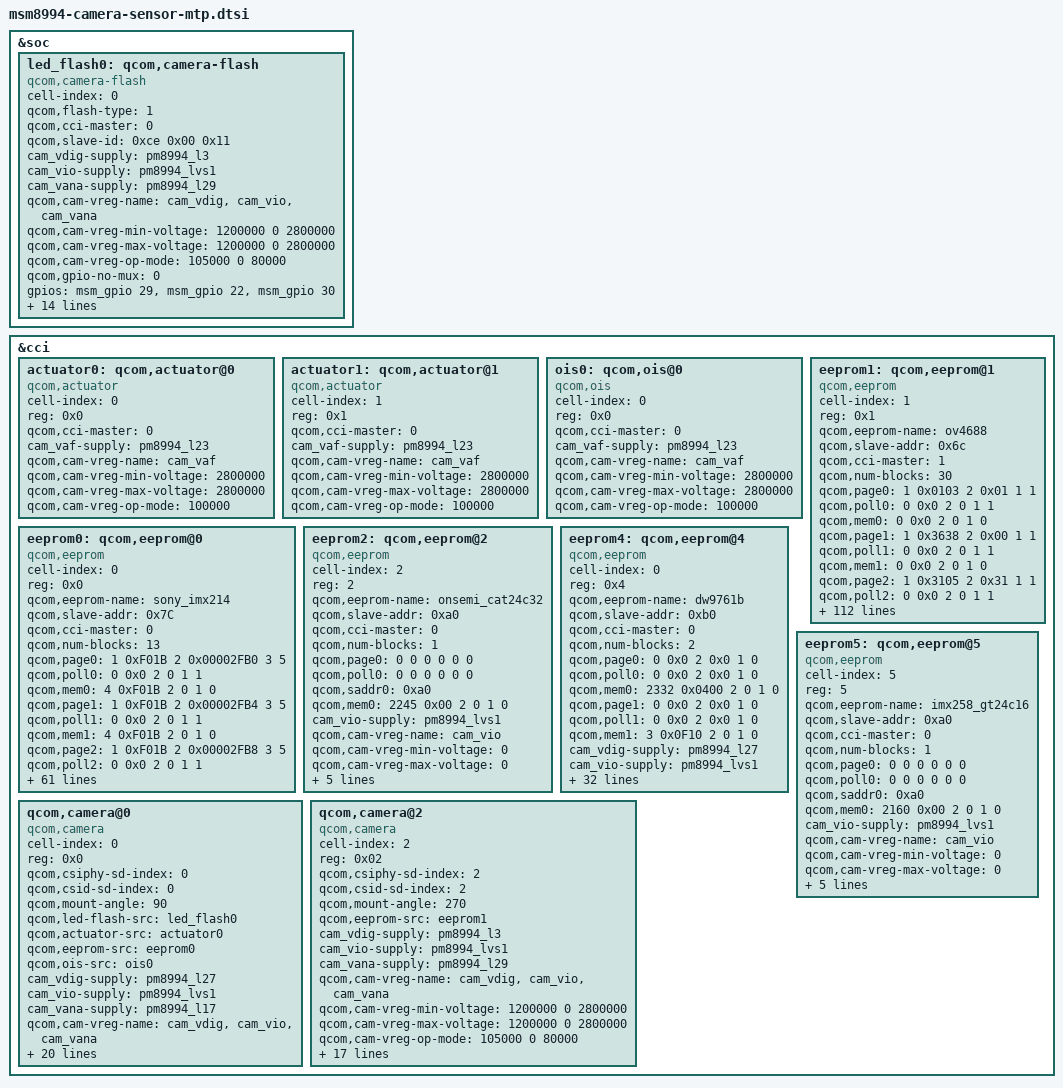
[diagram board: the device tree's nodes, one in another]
/*
 * Copyright (c) 2014-2016, The Linux Foundation. All rights reserved.
 * Copyright (C) 2018 XiaoMi, Inc.
 *
 * This program is free software; you can redistribute it and/or modify
 * it under the terms of the GNU General Public License version 2 and
 * only version 2 as published by the Free Software Foundation.
 *
 * This program is distributed in the hope that it will be useful,
 * but WITHOUT ANY WARRANTY; without even the implied warranty of
 * MERCHANTABILITY or FITNESS FOR A PARTICULAR PURPOSE.  See the
 * GNU General Public License for more details.
 */

&soc {

	led_flash0: qcom,camera-flash {
		cell-index = <0>;
		compatible = "qcom,camera-flash";
		qcom,flash-type = <1>;
		qcom,cci-master = <0>;
        qcom,slave-id = <0xce 0x00 0x11>;

		cam_vdig-supply = <&pm8994_l3>;
		cam_vio-supply = <&pm8994_lvs1>;
		cam_vana-supply = <&pm8994_l29>;
		qcom,cam-vreg-name = "cam_vdig", "cam_vio", "cam_vana";
		qcom,cam-vreg-min-voltage = <1200000 0 2800000>;
		qcom,cam-vreg-max-voltage = <1200000 0 2800000>;
		qcom,cam-vreg-op-mode = <105000 0 80000>;

		qcom,gpio-no-mux = <0>;
		gpios = <&msm_gpio 29 0>,
			<&msm_gpio 22 0>,
			<&msm_gpio 30 0>;
		qcom,gpio-flash-en = <0>;
		qcom,gpio-flash-now = <1>;
		qcom,gpio-flash-reset = <2>;
		qcom,gpio-req-tbl-num = <0 1 2>;
		qcom,gpio-req-tbl-flags = <0 0 0>;
		qcom,gpio-req-tbl-label = "FLASH_EN", "FLASH_NOW", "FLASH_RESET";
		qcom,cam-power-seq-type = "sensor_vreg", "sensor_gpio", "sensor_gpio", "sensor_gpio";
		qcom,cam-power-seq-val = "cam_vio", "sensor_gpio_fl_en", "sensor_gpio_fl_now","sensor_gpio_fl_reset";
		qcom,cam-power-seq-cfg-val = <1 0 0 0>;
		qcom,cam-power-seq-delay = <1 1 1 1>;
	};

};

&cci {
        /*led_flash0: qcom,led-flash@66 {
                cell-index = <0>;
                reg = <0xce>;
                qcom,slave-id = <0xce 0x00 0x11>;
                compatible = "qcom,camera-flash";
                label = "lm3646";
                qcom,flash-type = <1>;
                qcom,gpio-no-mux = <0>;
                gpios = <&msm_gpio 29 0>,
                        <&msm_gpio 22 0>;
                qcom,gpio-flash-en = <0>;
                qcom,gpio-flash-now = <1>;
                qcom,gpio-req-tbl-num = <0 1>;
                qcom,gpio-req-tbl-flags = <0 0>;
                qcom,gpio-req-tbl-label = "FLASH_EN", "FLASH_NOW";
                qcom,cci-master = <0>;
        };*/

	actuator0: qcom,actuator@0 {
		cell-index = <0>;
		reg = <0x0>;
		compatible = "qcom,actuator";
		qcom,cci-master = <0>;
		cam_vaf-supply = <&pm8994_l23>;
		qcom,cam-vreg-name = "cam_vaf";
		qcom,cam-vreg-min-voltage = <2800000>;
		qcom,cam-vreg-max-voltage = <2800000>;
		qcom,cam-vreg-op-mode = <100000>;
	};

	actuator1: qcom,actuator@1 {
		cell-index = <1>;
		reg = <0x1>;
		compatible = "qcom,actuator";
		qcom,cci-master = <0>;
		cam_vaf-supply = <&pm8994_l23>;
		qcom,cam-vreg-name = "cam_vaf";
		qcom,cam-vreg-min-voltage = <2800000>;
		qcom,cam-vreg-max-voltage = <2800000>;
		qcom,cam-vreg-op-mode = <100000>;
	};


	ois0: qcom,ois@0 {
		cell-index = <0>;
		reg = <0x0>;
		compatible = "qcom,ois";
		qcom,cci-master = <0>;
		cam_vaf-supply = <&pm8994_l23>;
		qcom,cam-vreg-name = "cam_vaf";
		qcom,cam-vreg-min-voltage = <2800000>;
		qcom,cam-vreg-max-voltage = <2800000>;
		qcom,cam-vreg-op-mode = <100000>;
	};

	eeprom0: qcom,eeprom@0 {
		cell-index = <0>;
		reg = <0x0>;
		qcom,eeprom-name = "sony_imx214";
		compatible = "qcom,eeprom";
		qcom,slave-addr = <0x7C>;
		qcom,cci-master = <0>;
		qcom,num-blocks = <13>;

		qcom,page0 = <1 0xF01B 2 0x00002FB0 3 5>;
		qcom,poll0 = <0 0x0 2 0 1 1>;
		qcom,mem0 = <4 0xF01B 2 0 1 0>;

		qcom,page1 = <1 0xF01B 2 0x00002FB4 3 5>;
		qcom,poll1 = <0 0x0 2 0 1 1>;
		qcom,mem1 = <4 0xF01B 2 0 1 0>;

		qcom,page2 = <1 0xF01B 2 0x00002FB8 3 5>;
		qcom,poll2 = <0 0x0 2 0 1 1>;
		qcom,mem2 = <4 0xF01B 2 0 1 0>;

		qcom,page3 = <1 0xF01B 2 0x00002FBC 3 5>;
		qcom,poll3 = <0 0x0 2 0 1 1>;
		qcom,mem3 = <4 0xF01B 2 0 1 0>;

		qcom,page4 = <1 0xF01B 2 0x00002FC0 3 5>;
		qcom,poll4 = <0 0x0 2 0 1 1>;
		qcom,mem4 = <4 0xF01B 2 0 1 0>;

		qcom,page5 = <1 0xF01B 2 0x00002FC4 3 5>;
		qcom,poll5 = <0 0x0 2 0 1 1>;
		qcom,mem5 = <4 0xF01B 2 0 1 0>;

		qcom,page6 = <1 0xF01B 2 0x00002FC8 3 5>;
		qcom,poll6 = <0 0x0 2 0 1 1>;
		qcom,mem6 = <4 0xF01B 2 0 1 0>;

		qcom,page7 = <1 0xF01B 2 0x00002FCC 3 5>;
		qcom,poll7 = <0 0x0 2 0 1 1>;
		qcom,mem7 = <4 0xF01B 2 0 1 0>;

		qcom,page8 = <1 0xF01B 2 0x00002FD0 3 5>;
		qcom,poll8 = <0 0x0 2 0 1 1>;
		qcom,mem8 = <4 0xF01B 2 0 1 0>;

		qcom,page9 = <1 0xF01B 2 0x00002FD4 3 5>;
		qcom,poll9 = <0 0x0 2 0 1 1>;
		qcom,mem9 = <4 0xF01B 2 0 1 0>;

		qcom,page10 = <1 0xF01B 2 0x00002FD8 3 5>;
		qcom,poll10 = <0 0x0 2 0 1 1>;
		qcom,mem10 = <4 0xF01B 2 0 1 0>;

		qcom,page11 = <1 0xF01B 2 0x00002FDC 3 5>;
		qcom,poll11 = <0 0x0 2 0 1 1>;
		qcom,mem11 = <4 0xF01B 2 0 1 0>;

		qcom,page12 = <1 0xF01B 2 0x00002FDE 3 5>;
		qcom,poll12 = <0 0x0 2 0 1 1>;
		qcom,mem12 = <4 0xF01B 2 0 1 0>;

		cam_vdig-supply = <&pm8994_l27>;
		cam_vio-supply = <&pm8994_lvs1>;
		cam_vana-supply = <&pm8994_l17>;
		qcom,cam-vreg-name = "cam_vdig", "cam_vio", "cam_vana";
		qcom,cam-vreg-min-voltage = <1050000 0 2700000>;
		qcom,cam-vreg-max-voltage = <1050000 0 2700000>;
		qcom,cam-vreg-op-mode = <105000 0 80000>;
		qcom,gpio-no-mux = <0>;
		pinctrl-names = "cam_default", "cam_suspend";
		pinctrl-0 = <&cam_sensor_mclk0_active &cam_sensor_rear_active>;
		pinctrl-1 = <&cam_sensor_mclk0_suspend &cam_sensor_rear_suspend>;
		gpios = <&msm_gpio 13 0>,
			<&msm_gpio 16 0>,
			<&msm_gpio 91 0>;
		qcom,gpio-reset = <1>;
		qcom,gpio-standby = <2>;
		qcom,gpio-req-tbl-num = <0 1 2>;
		qcom,gpio-req-tbl-flags = <1 0 0>;
		qcom,gpio-req-tbl-label = "CAMIF_MCLK0",
					  "CAM_RESET0",
					  "CAM_STANDBY0";
		qcom,cam-power-seq-type = "sensor_gpio", "sensor_vreg", "sensor_vreg",
			"sensor_vreg", "sensor_gpio" , "sensor_clk";
		qcom,cam-power-seq-val = "sensor_gpio_reset", "cam_vdig", "cam_vana",
			"cam_vio", "sensor_gpio_standby","sensor_cam_mclk";
		qcom,cam-power-seq-cfg-val = <1 1 1 1 1 24000000>;
		qcom,cam-power-seq-delay = <1 1 1 30 30 5>;
		status = "ok";
		clocks = <&clock_mmss clk_mclk0_clk_src>,
				<&clock_mmss clk_camss_mclk0_clk>;
		clock-names = "cam_src_clk", "cam_clk";
	};

	eeprom1: qcom,eeprom@1 {
		cell-index = <1>;
		reg = <0x1>;
		qcom,eeprom-name = "ov4688";
		compatible = "qcom,eeprom";
		qcom,slave-addr = <0x6c>;
		qcom,cci-master = <1>;
		qcom,num-blocks = <30>;

		qcom,page0 = <1 0x0103 2 0x01 1 1>;
		qcom,poll0 = <0 0x0 2 0 1 1>;
		qcom,mem0 = <0 0x0 2 0 1 0>;

		qcom,page1 = <1 0x3638 2 0x00 1 1>;
		qcom,poll1 = <0 0x0 2 0 1 1>;
		qcom,mem1 = <0 0x0 2 0 1 0>;

		qcom,page2 = <1 0x3105 2 0x31 1 1>;
		qcom,poll2 = <0 0x0 2 0 1 1>;
		qcom,mem2 = <0 0x0 2 0 1 0>;

		qcom,page3 = <1 0x310a 2 0xf9 1 1>;
		qcom,poll3 = <0 0x0 2 0 1 1>;
		qcom,mem3 = <0 0x0 2 0 1 0>;

		qcom,page4 = <1 0x3508 2 0x07 1 1>;
		qcom,poll4 = <0 0x0 2 0 1 1>;
		qcom,mem4 = <0 0x0 2 0 1 0>;

		qcom,page5 = <1 0x484b 2 0x05 1 1>;
		qcom,poll5 = <0 0x0 2 0 1 1>;
		qcom,mem5 = <0 0x0 2 0 1 0>;

		qcom,page6 = <1 0x4805 2 0x03 1 1>;
		qcom,poll6 = <0 0x0 2 0 1 1>;
		qcom,mem6 = <0 0x0 2 0 1 0>;

		qcom,page7 = <1 0x3601 2 0x01 1 1>;
		qcom,poll7 = <0 0x0 2 0 1 1>;
		qcom,mem7 = <0 0x0 2 0 1 0>;

		qcom,page8 = <1 0x0100 2 0x01 1 1>;
		qcom,poll8 = <0 0x0 2 0 1 1>;
		qcom,mem8 = <0 0x0 2 0 1 0>;

		qcom,page9 = <1 0x3105 2 0x11 1 1>;
		qcom,poll9 = <0 0x0 2 0 1 1>;
		qcom,mem9 = <0 0x0 2 0 1 0>;

		qcom,page10 = <1 0x301a 2 0xf1 1 1>;
		qcom,poll10 = <0 0x0 2 0 1 1>;
		qcom,mem10 = <0 0x0 2 0 1 0>;

		qcom,page11 = <1 0x4805 2 0x00 1 1>;
		qcom,poll11 = <0 0x0 2 0 1 1>;
		qcom,mem11 = <0 0x0 2 0 1 0>;

		qcom,page12 = <1 0x301a 2 0xf0 1 1>;
		qcom,poll12 = <0 0x0 2 0 1 1>;
		qcom,mem12 = <0 0x0 2 0 1 0>;

		qcom,page13 = <1 0x3208 2 0x00 1 1>;
		qcom,poll13 = <0 0x0 2 0 1 1>;
		qcom,mem13 = <0 0x0 2 0 1 0>;

		qcom,page14 = <1 0x302a 2 0x00 1 1>;
		qcom,poll14 = <0 0x0 2 0 1 1>;
		qcom,mem14 = <0 0x0 2 0 1 0>;

		qcom,page15 = <1 0x302a 2 0x00 1 1>;
		qcom,poll15 = <0 0x0 2 0 1 1>;
		qcom,mem15 = <0 0x0 2 0 1 0>;

		qcom,page16 = <1 0x302a 2 0x00 1 1>;
		qcom,poll16 = <0 0x0 2 0 1 1>;
		qcom,mem16 = <0 0x0 2 0 1 0>;

		qcom,page17 = <1 0x302a 2 0x00 1 1>;
		qcom,poll17 = <0 0x0 2 0 1 1>;
		qcom,mem17 = <0 0x0 2 0 1 0>;

		qcom,page18 = <1 0x302a 2 0x00 1 1>;
		qcom,poll18 = <0 0x0 2 0 1 1>;
		qcom,mem18 = <0 0x0 2 0 1 0>;

		qcom,page19 = <1 0x3601 2 0x00 1 1>;
		qcom,poll19 = <0 0x0 2 0 1 1>;
		qcom,mem19 = <0 0x0 2 0 1 0>;

		qcom,page20 = <1 0x3638 2 0x00 1 1>;
		qcom,poll20 = <0 0x0 2 0 1 1>;
		qcom,mem20 = <0 0x0 2 0 1 0>;

		qcom,page21 = <1 0x3208 2 0x10 1 1>;
		qcom,poll21 = <0 0x0 2 0 1 1>;
		qcom,mem21 = <0 0x0 2 0 1 0>;

		qcom,page22 = <1 0x3208 2 0xa0 1 1>;
		qcom,poll22 = <0 0x0 2 0 1 1>;
		qcom,mem22 = <0 0x0 2 0 1 0>;

		qcom,page23 = <1 0x3d84 2 0xc0 1 1>;
		qcom,poll23 = <0 0x0 2 0 1 1>;
		qcom,mem23 = <0 0x0 2 0 1 0>;

		qcom,page24 = <1 0x3d88 2 0x71 1 1>;
		qcom,poll24 = <0 0x0 2 0 1 1>;
		qcom,mem24 = <0 0x0 2 0 1 0>;

		qcom,page25 = <1 0x3d89 2 0x10 1 1>;
		qcom,poll25 = <0 0x0 2 0 1 1>;
		qcom,mem25 = <0 0x0 2 0 1 0>;

		qcom,page26 = <1 0x3d8a 2 0x71 1 1>;
		qcom,poll26 = <0 0x0 2 0 1 1>;
		qcom,mem26 = <0 0x0 2 0 1 0>;

		qcom,page27 = <1 0x3d8b 2 0x3F 1 1>;
		qcom,poll27 = <0 0x0 2 0 1 1>;
		qcom,mem27 = <0 0x0 2 0 1 0>;

		qcom,page28 = <1 0x7110 2 0x0 1 1>;
		qcom,poll28 = <0 0x0 2 0 1 1>;
		qcom,mem28 = <0 0x0 2 0 1 0>;

		qcom,page29 = <1 0x3d81 2 0x01 1 10>;
		qcom,poll29 = <0 0x0 2 0 1 1>;
		qcom,mem29 = <48 0x7110 2 0 1 0>;

		cam_vdig-supply = <&pm8994_l3>;
		cam_vio-supply = <&pm8994_lvs1>;
		cam_vana-supply = <&pm8994_l29>;
		qcom,cam-vreg-name = "cam_vdig", "cam_vio", "cam_vana";
		qcom,cam-vreg-min-voltage = <1200000 0 2800000>;
		qcom,cam-vreg-max-voltage = <1200000 0 2800000>;
		qcom,cam-vreg-op-mode = <105000 0 80000>;
		qcom,gpio-no-mux = <0>;
		pinctrl-names = "cam_default", "cam_suspend";
		pinctrl-0 = <&cam_sensor_mclk2_active &cam_sensor_front_active>;
		pinctrl-1 = <&cam_sensor_mclk2_suspend &cam_sensor_front_suspend>;
		gpios = <&msm_gpio 15 0>,
			<&msm_gpio 104 0>,
			<&msm_gpio 105 0>;
		qcom,gpio-reset = <1>;
		qcom,gpio-standby = <2>;
		qcom,gpio-req-tbl-num = <0 1 2>;
		qcom,gpio-req-tbl-flags = <1 0 0>;
		qcom,gpio-req-tbl-label = "CAMIF_MCLK2",
					  "CAM_RESET2",
					  "CAM_STANDBY2";
		qcom,cam-power-seq-type = "sensor_vreg", "sensor_vreg", "sensor_vreg",
			"sensor_gpio", "sensor_gpio" , "sensor_clk";
		qcom,cam-power-seq-val = "cam_vdig", "cam_vana", "cam_vio",
			"sensor_gpio_reset", "sensor_gpio_standby","sensor_cam_mclk";
		qcom,cam-power-seq-cfg-val = <1 1 1 1 1 24000000>;
		qcom,cam-power-seq-delay = <1 1 1 30 30 5>;
		status = "ok";
		clocks = <&clock_mmss clk_mclk2_clk_src>,
				<&clock_mmss clk_camss_mclk2_clk>;
		clock-names = "cam_src_clk", "cam_clk";
	};

	eeprom2: qcom,eeprom@2 {
		cell-index = <2>;
		reg = <2>;
		qcom,eeprom-name = "onsemi_cat24c32";
		compatible = "qcom,eeprom";
		qcom,slave-addr = <0xa0>;
		qcom,cci-master = <0>;
		qcom,num-blocks = <1>;
		qcom,page0 = <0 0 0 0 0 0>;
		qcom,poll0 = <0 0 0 0 0 0>;
		qcom,saddr0 = <0xa0>;
		qcom,mem0 = <2245 0x00 2 0 1 0>;

		cam_vio-supply = <&pm8994_lvs1>;
		qcom,cam-vreg-name = "cam_vio";
		qcom,cam-vreg-min-voltage = <0>;
		qcom,cam-vreg-max-voltage = <0>;
		qcom,cam-vreg-op-mode = <0>;
		qcom,cam-power-seq-type = "sensor_vreg";
		qcom,cam-power-seq-val = "cam_vio";
		qcom,cam-power-seq-cfg-val = <1>;
		qcom,cam-power-seq-delay = <1>;
		status = "ok";
	};

	eeprom4: qcom,eeprom@4 {
		cell-index = <0>;
		reg = <0x4>;
		qcom,eeprom-name = "dw9761b";
		compatible = "qcom,eeprom";
		qcom,slave-addr = <0xb0>;
		qcom,cci-master = <0>;
		qcom,num-blocks = <2>;

		qcom,page0 = <0 0x0 2 0x0 1 0>;
		qcom,poll0 = <0 0x0 2 0x0 1 0>;
		qcom,mem0 = <2332 0x0400 2 0 1 0>;

		qcom,page1 = <0 0x0 2 0x0 1 0>;
		qcom,poll1 = <0 0x0 2 0x0 1 0>;
		qcom,mem1 = <3 0x0F10 2 0 1 0>;

		cam_vdig-supply = <&pm8994_l27>;
		cam_vio-supply = <&pm8994_lvs1>;
		cam_vana-supply = <&pm8994_l17>;
		cam_vaf-supply = <&pm8994_l23>;
		qcom,cam-vreg-name = "cam_vdig", "cam_vio", "cam_vana", "cam_vaf";
		qcom,cam-vreg-min-voltage = <1050000 0 2700000 2800000>;
		qcom,cam-vreg-max-voltage = <1050000 0 2700000 2800000>;
		qcom,cam-vreg-op-mode = <105000 0 80000 100000>;
		qcom,gpio-no-mux = <0>;
		pinctrl-names = "cam_default", "cam_suspend";
		pinctrl-0 = <&cam_sensor_mclk0_active &cam_sensor_rear_active>;
		pinctrl-1 = <&cam_sensor_mclk0_suspend &cam_sensor_rear_suspend>;
		gpios = <&msm_gpio 13 0>,
			<&msm_gpio 92 0>,
			<&msm_gpio 91 0>;
		qcom,gpio-reset = <1>;
		qcom,gpio-standby = <2>;
		qcom,gpio-req-tbl-num = <0 1 2>;
		qcom,gpio-req-tbl-flags = <1 0 0>;
		qcom,gpio-req-tbl-label = "CAMIF_MCLK0",
					  "CAM_RESET0",
					  "CAM_STANDBY0";
		qcom,cam-power-seq-type = "sensor_vreg", "sensor_vreg",
			"sensor_vreg", "sensor_vreg", "sensor_gpio",
			"sensor_gpio" , "sensor_clk";
		qcom,cam-power-seq-val = "cam_vdig", "cam_vana", "cam_vio",
			"cam_vaf", "sensor_gpio_reset", "sensor_gpio_standby",
			"sensor_cam_mclk";
		qcom,cam-power-seq-cfg-val = <1 1 1 1 1 1 24000000>;
		qcom,cam-power-seq-delay = <1 1 1 1 30 30 5>;
		status = "ok";
		clocks = <&clock_mmss clk_mclk0_clk_src>,
				<&clock_mmss clk_camss_mclk0_clk>;
		clock-names = "cam_src_clk", "cam_clk";
	};

	eeprom5: qcom,eeprom@5 {
		cell-index = <5>;
		reg = <5>;
		qcom,eeprom-name = "imx258_gt24c16";
		compatible = "qcom,eeprom";
		qcom,slave-addr = <0xa0>;
		qcom,cci-master = <0>;
		qcom,num-blocks = <1>;
		qcom,page0 = <0 0 0 0 0 0>;
		qcom,poll0 = <0 0 0 0 0 0>;
		qcom,saddr0 = <0xa0>;
		qcom,mem0 = <2160 0x00 2 0 1 0>;

		cam_vio-supply = <&pm8994_lvs1>;
		qcom,cam-vreg-name = "cam_vio";
		qcom,cam-vreg-min-voltage = <0>;
		qcom,cam-vreg-max-voltage = <0>;
		qcom,cam-vreg-op-mode = <0>;
		qcom,cam-power-seq-type = "sensor_vreg";
		qcom,cam-power-seq-val = "cam_vio";
		qcom,cam-power-seq-cfg-val = <1>;
		qcom,cam-power-seq-delay = <1>;
		status = "ok";
	};

	qcom,camera@0 {
		cell-index = <0>;
		compatible = "qcom,camera";
		reg = <0x0>;
		qcom,csiphy-sd-index = <0>;
		qcom,csid-sd-index = <0>;
		qcom,mount-angle = <90>;
		qcom,led-flash-src = <&led_flash0>;
		qcom,actuator-src = <&actuator0>;
		qcom,eeprom-src = <&eeprom0>;
		qcom,ois-src = <&ois0>;
		cam_vdig-supply = <&pm8994_l27>;
		cam_vio-supply = <&pm8994_lvs1>;
		cam_vana-supply = <&pm8994_l17>;
		qcom,cam-vreg-name = "cam_vdig", "cam_vio", "cam_vana";
		qcom,cam-vreg-min-voltage = <1050000 0 2700000>;
		qcom,cam-vreg-max-voltage = <1050000 0 2700000>;
		qcom,cam-vreg-op-mode = <105000 0 80000>;
		qcom,gpio-no-mux = <0>;
		pinctrl-names = "cam_default", "cam_suspend";
		pinctrl-0 = <&cam_sensor_mclk0_active &cam_sensor_rear_active>;
		pinctrl-1 = <&cam_sensor_mclk0_suspend &cam_sensor_rear_suspend>;
		gpios = <&msm_gpio 13 0>,
			<&msm_gpio 16 0>,
			<&msm_gpio 91 0>;
		qcom,gpio-reset = <1>;
		qcom,gpio-standby = <2>;
		qcom,gpio-req-tbl-num = <0 1 2>;
		qcom,gpio-req-tbl-flags = <1 0 0>;
		qcom,gpio-req-tbl-label = "CAMIF_MCLK0",
					  "CAM_RESET0",
					  "CAM_STANDBY0";
		qcom,sensor-position = <0>;
		qcom,sensor-mode = <0>;
		qcom,cci-master = <0>;
		status = "ok";
		clocks = <&clock_mmss clk_mclk0_clk_src>,
				<&clock_mmss clk_camss_mclk0_clk>;
		clock-names = "cam_src_clk", "cam_clk";
	};

	qcom,camera@2 {
		cell-index = <2>;
		compatible = "qcom,camera";
		reg = <0x02>;
		qcom,csiphy-sd-index = <2>;
		qcom,csid-sd-index = <2>;
		qcom,mount-angle = <270>;
		qcom,eeprom-src = <&eeprom1>;
		cam_vdig-supply = <&pm8994_l3>;
		cam_vio-supply = <&pm8994_lvs1>;
		cam_vana-supply = <&pm8994_l29>;
		qcom,cam-vreg-name = "cam_vdig", "cam_vio", "cam_vana";
		qcom,cam-vreg-min-voltage = <1200000 0 2800000>;
		qcom,cam-vreg-max-voltage = <1200000 0 2800000>;
		qcom,cam-vreg-op-mode = <105000 0 80000>;
		qcom,gpio-no-mux = <0>;
		pinctrl-names = "cam_default", "cam_suspend";
		pinctrl-0 = <&cam_sensor_mclk2_active &cam_sensor_front_active>;
		pinctrl-1 = <&cam_sensor_mclk2_suspend &cam_sensor_front_suspend>;
		gpios = <&msm_gpio 15 0>,
			<&msm_gpio 104 0>,
			<&msm_gpio 105 0>;
		qcom,gpio-reset = <1>;
		qcom,gpio-standby = <2>;
		qcom,gpio-req-tbl-num = <0 1 2>;
		qcom,gpio-req-tbl-flags = <1 0 0>;
		qcom,gpio-req-tbl-label = "CAMIF_MCLK2",
					  "CAM_RESET2",
					  "CAM_STANDBY2";
		qcom,sensor-position = <1>;
		qcom,sensor-mode = <0>;
		qcom,cci-master = <1>;
		status = "ok";
		clocks = <&clock_mmss clk_mclk2_clk_src>,
			<&clock_mmss clk_camss_mclk2_clk>;
		clock-names = "cam_src_clk", "cam_clk";
	};
};
